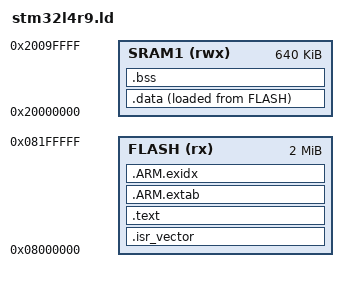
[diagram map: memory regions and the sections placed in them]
/*
 * stm32l4r9.ld — linker script for STM32L4R9VIT6
 * Author: jayis1
 * License: MIT
 *
 * 2 MB Flash, 640 KB SRAM1+SRAM2. The HydroFluor firmware runs entirely
 * from flash with the stack in SRAM2 and the .bss/.data in SRAM1.
 */
MEMORY
{
    FLASH (rx)  : ORIGIN = 0x08000000, LENGTH = 2048K
    SRAM1 (rwx) : ORIGIN = 0x20000000, LENGTH = 640K
}

_estack = ORIGIN(SRAM1) + LENGTH(SRAM1);

SECTIONS
{
    .isr_vector : {
        . = ALIGN(4);
        KEEP(*(.isr_vector))
        . = ALIGN(4);
    } > FLASH

    .text : {
        . = ALIGN(4);
        *(.text)
        *(.text*)
        *(.rodata)
        *(.rodata*)
        *(.glue_7)
        *(.glue_7t)
        *(.eh_frame)
        . = ALIGN(4);
        _etext = .;
    } > FLASH

    .ARM.extab : { *(.ARM.extab* .gnu.linkonce.armextab.*) } > FLASH
    .ARM.exidx : {
        __exidx_start = .;
        *(.ARM.exidx* .gnu.linkonce.armexidx.*)
        __exidx_end = .;
    } > FLASH

    .data : {
        . = ALIGN(4);
        _sdata = .;
        *(.data)
        *(.data*)
        . = ALIGN(4);
        _edata = .;
    } > SRAM1 AT > FLASH
    _sidata = LOADADDR(.data);

    .bss : {
        . = ALIGN(4);
        _sbss = .;
        *(.bss)
        *(.bss*)
        *(COMMON)
        . = ALIGN(4);
        _ebss = .;
    } > SRAM1
}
